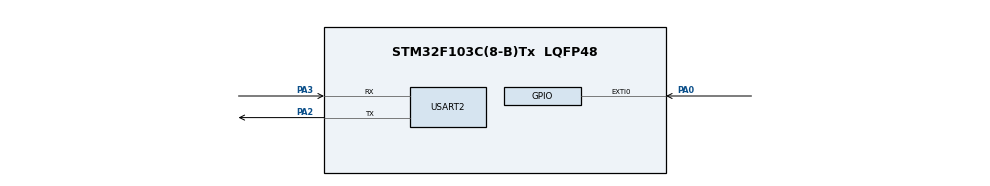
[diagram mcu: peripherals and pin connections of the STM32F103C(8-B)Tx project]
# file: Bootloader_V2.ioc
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Mcu.Family=STM32F1
Mcu.Name=STM32F103C(8-B)Tx
Mcu.Package=LQFP48
NVIC.EXTI0_IRQn=true\:0\:0\:false\:false\:true\:true\:true\:true
NVIC.PriorityGroup=NVIC_PRIORITYGROUP_4
PA0-WKUP.GPIO_ModeDefaultEXTI=GPIO_MODE_IT_RISING
PA0-WKUP.GPIO_PuPd=GPIO_PULLDOWN
PA0-WKUP.Signal=GPXTI0
PA2.Mode=Asynchronous
PA2.Signal=USART2_TX
PA3.Mode=Asynchronous
PA3.Signal=USART2_RX
ProjectManager.HeapSize=0x200
ProjectManager.StackSize=0x400
ProjectManager.TargetToolchain=STM32CubeIDE
RCC.APB1Freq_Value=8000000
RCC.APB2Freq_Value=8000000
TIM1.Period=50000-1
TIM1.Prescaler=160-1
USART2.VirtualMode=VM_ASYNC
VP_CRC_VS_CRC.Mode=CRC_Activate
VP_TIM1_VS_ClockSourceINT.Mode=Internal
board=custom

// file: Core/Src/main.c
/* USER CODE BEGIN Header */
/**
 ******************************************************************************
 * @file           : main.c
 * @brief          : Main program body
 ******************************************************************************
 * @attention
 *
 * Copyright (c) 2024 STMicroelectronics.
 * All rights reserved.
 *
 * This software is licensed under terms that can be found in the LICENSE file
 * in the root directory of this software component.
 * If no LICENSE file comes with this software, it is provided AS-IS.
 *
 ******************************************************************************
 */
/* USER CODE END Header */
#include "main.h"

/* USER CODE BEGIN Includes */
#include "Bootloader.h"
/* USER CODE END Includes */

CRC_HandleTypeDef hcrc;

TIM_HandleTypeDef htim1;

UART_HandleTypeDef huart2;

void SystemClock_Config(void);
static void MX_GPIO_Init(void);
static void MX_CRC_Init(void);
static void MX_USART2_UART_Init(void);
static void MX_TIM1_Init(void);

/* USER CODE BEGIN 0 */
uint8_t Flag3=0;
/* USER CODE END 0 */

int main(void)
{

  /* MCU Configuration--------------------------------------------------------*/

  /* Reset of all peripherals, Initializes the Flash interface and the Systick. */
  HAL_Init();

  /* Configure the system clock */
  SystemClock_Config();

  /* Initialize all configured peripherals */
  MX_GPIO_Init();
  MX_CRC_Init();
  MX_USART2_UART_Init();
  MX_TIM1_Init();
  /* USER CODE BEGIN 2 */
	uint8_t Flag1=0;
	uint8_t EraseState=0;
  /* USER CODE END 2 */

  /* Infinite loop */
  /* USER CODE BEGIN WHILE */
	while (1)
	{
		//Jump_Application();
		uint8_t d=Bootloader_voidCheckStartCommand();
		if(Flag1 == 0)
		{
			Flag1=1;
			EraseState = Bootloader_uint8FlashErase(0xff,12);
		}
		if(Flag3==1)
		{
			Bootloader_voidJumpToApp();
		}

		/*State = HAL_GPIO_ReadPin(GPIOA, GPIO_PIN_0);
		if(State == GPIO_PIN_SET)
		{
			Jump_Application();
		}*/
		//uint8_t d=Bootloader_voidCheckStartCommand();
		if(d== 1)
		{
			//HAL_UART_Receive(&huart2, &hh, 1, HAL_MAX_DELAY);
			/*if(Flag1 == 0)
			{
				Flag1=1;
				EraseState = Perform_Flash_Erase(0xff,12);
			}*/

			Bootloader_enumRecHostCommands();
			//Jump_Application();
		}
		/*else if(Flag3 == 0x1)
		{
			Jump_Application();
		}
		else
		{

		}*/
    /* USER CODE END WHILE */

	}
}

void SystemClock_Config(void)
{
  RCC_OscInitTypeDef RCC_OscInitStruct = {0};
  RCC_ClkInitTypeDef RCC_ClkInitStruct = {0};

  /** Initializes the RCC Oscillators according to the specified parameters
  * in the RCC_OscInitTypeDef structure.
  */
  RCC_OscInitStruct.OscillatorType = RCC_OSCILLATORTYPE_HSI;
  RCC_OscInitStruct.HSIState = RCC_HSI_ON;
  RCC_OscInitStruct.HSICalibrationValue = RCC_HSICALIBRATION_DEFAULT;
  RCC_OscInitStruct.PLL.PLLState = RCC_PLL_NONE;
  if (HAL_RCC_OscConfig(&RCC_OscInitStruct) != HAL_OK)
  {
    Error_Handler();
  }

  /** Initializes the CPU, AHB and APB buses clocks
  */
  RCC_ClkInitStruct.ClockType = RCC_CLOCKTYPE_HCLK|RCC_CLOCKTYPE_SYSCLK
                              |RCC_CLOCKTYPE_PCLK1|RCC_CLOCKTYPE_PCLK2;
  RCC_ClkInitStruct.SYSCLKSource = RCC_SYSCLKSOURCE_HSI;
  RCC_ClkInitStruct.AHBCLKDivider = RCC_SYSCLK_DIV1;
  RCC_ClkInitStruct.APB1CLKDivider = RCC_HCLK_DIV1;
  RCC_ClkInitStruct.APB2CLKDivider = RCC_HCLK_DIV1;

  if (HAL_RCC_ClockConfig(&RCC_ClkInitStruct, FLASH_LATENCY_0) != HAL_OK)
  {
    Error_Handler();
  }
}

static void MX_CRC_Init(void)
{

  hcrc.Instance = CRC;
  if (HAL_CRC_Init(&hcrc) != HAL_OK)
  {
    Error_Handler();
  }

}

static void MX_TIM1_Init(void)
{

  TIM_ClockConfigTypeDef sClockSourceConfig = {0};
  TIM_MasterConfigTypeDef sMasterConfig = {0};

  htim1.Instance = TIM1;
  htim1.Init.Prescaler = 160-1;
  htim1.Init.CounterMode = TIM_COUNTERMODE_UP;
  htim1.Init.Period = 50000-1;
  htim1.Init.ClockDivision = TIM_CLOCKDIVISION_DIV1;
  htim1.Init.RepetitionCounter = 0;
  htim1.Init.AutoReloadPreload = TIM_AUTORELOAD_PRELOAD_DISABLE;
  if (HAL_TIM_Base_Init(&htim1) != HAL_OK)
  {
    Error_Handler();
  }
  sClockSourceConfig.ClockSource = TIM_CLOCKSOURCE_INTERNAL;
  if (HAL_TIM_ConfigClockSource(&htim1, &sClockSourceConfig) != HAL_OK)
  {
    Error_Handler();
  }
  sMasterConfig.MasterOutputTrigger = TIM_TRGO_RESET;
  sMasterConfig.MasterSlaveMode = TIM_MASTERSLAVEMODE_DISABLE;
  if (HAL_TIMEx_MasterConfigSynchronization(&htim1, &sMasterConfig) != HAL_OK)
  {
    Error_Handler();
  }

}

static void MX_USART2_UART_Init(void)
{

  huart2.Instance = USART2;
  huart2.Init.BaudRate = 115200;
  huart2.Init.WordLength = UART_WORDLENGTH_8B;
  huart2.Init.StopBits = UART_STOPBITS_1;
  huart2.Init.Parity = UART_PARITY_NONE;
  huart2.Init.Mode = UART_MODE_TX_RX;
  huart2.Init.HwFlowCtl = UART_HWCONTROL_NONE;
  huart2.Init.OverSampling = UART_OVERSAMPLING_16;
  if (HAL_UART_Init(&huart2) != HAL_OK)
  {
    Error_Handler();
  }

}

static void MX_GPIO_Init(void)
{
  GPIO_InitTypeDef GPIO_InitStruct = {0};

  /* GPIO Ports Clock Enable */
  __HAL_RCC_GPIOA_CLK_ENABLE();

  /*Configure GPIO pin : PA0 */
  GPIO_InitStruct.Pin = GPIO_PIN_0;
  GPIO_InitStruct.Mode = GPIO_MODE_IT_RISING;
  GPIO_InitStruct.Pull = GPIO_PULLDOWN;
  HAL_GPIO_Init(GPIOA, &GPIO_InitStruct);

  /* EXTI interrupt init*/
  HAL_NVIC_SetPriority(EXTI0_IRQn, 0, 0);
  HAL_NVIC_EnableIRQ(EXTI0_IRQn);

}

/* USER CODE BEGIN 4 */
void HAL_GPIO_EXTI_Callback(uint16_t GPIO_Pin)
{
	//Jump_Application();
	Flag3=1;
	//Jump_Application();
}
/* USER CODE END 4 */

void Error_Handler(void)
{
	__disable_irq();
	while (1)
	{
	}
}
